# f29h85x_analog_subsys_regs register map
Vendor: Texas Instruments
Peripheral module from a debugger description file (folder HSM).
Registers are 32-bit, read-write, no defined reset value unless marked. A register's access mark holds for its fields unless they carry their own. Offsets are as the file gives them; lines under a group give offsets from that group; [hi:lo] are bit positions; {n}, {i} and the like mark numbered series; 'fields as' and 'values as' point back to an identical list; <NAME> marks a mode.

## ANALOG_SUBSYS_REGS — ANALOG SUBSYS Registers
0x44 PMMVREGTRIM — Power Management Module VREG Trim Register
  [7:0] VREGTRIM — Core VDD Voltage Regulator Trim
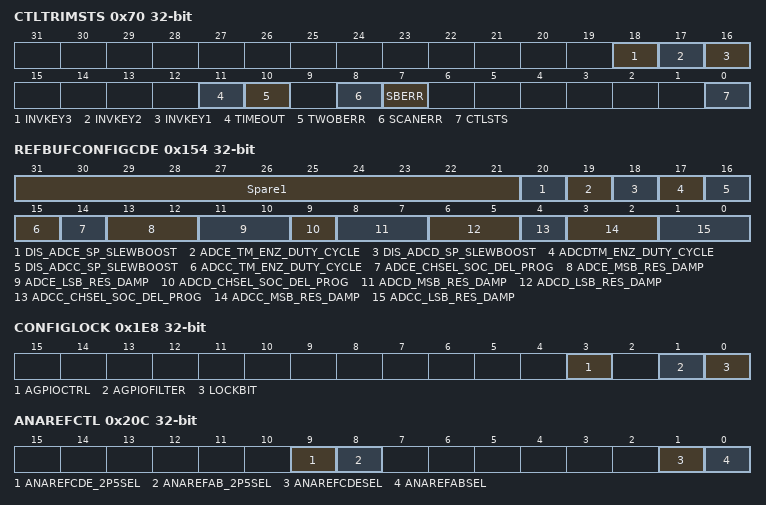
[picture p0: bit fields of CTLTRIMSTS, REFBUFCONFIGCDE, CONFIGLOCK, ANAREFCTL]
0x70 CTLTRIMSTS ro — HWCTL TRIM Error Status register
  [18] INVKEY3 — Invalid key read during TLC3
  [17] INVKEY2 — Invalid key read during TLC2
  [16] INVKEY1 — Invalid key read during TLC1
  [11] TIMEOUT — Timeout Error
  [10] TWOBERR — Two-bit error detected
  [8] SCANERR — Wrong scan chain signature
  [7] SBERR — Single-bit error detected while reading from Flash
  [0] CTLSTS — TRIM Load Complete
0x154 REFBUFCONFIGCDE — Config register for analog reference CDE
  [31:21] Spare1 — Spare1 bits
  [20] DIS_ADCE_SP_SLEWBOOST — ADC sp slew boost disbale
  [19] ADCE_TM_ENZ_DUTY_CYCLE — Disable Pulse Stretch testmode to have effect in ADC_CLK
  [18] DIS_ADCD_SP_SLEWBOOST — ADC sp slew boost disbale
  [17] ADCDTM_ENZ_DUTY_CYCLE — Disable Pulse Stretch testmode to have effect in ADC_CLK
  [16] DIS_ADCC_SP_SLEWBOOST — ADC sp slew boost disbale
  [15] ADCC_TM_ENZ_DUTY_CYCLE — Disable Pulse Stretch testmode to have effect in ADC_CLK
  [14] ADCE_CHSEL_SOC_DEL_PROG — CHSEL rise to ADCESOC rise delay program
  [13:12] ADCE_MSB_RES_DAMP — ADCE MSB damp res prog
  [11:10] ADCE_LSB_RES_DAMP — ADCE LSB damp res prog
  [9] ADCD_CHSEL_SOC_DEL_PROG — CHSEL rise to ADCDSOC rise delay program
  [8:7] ADCD_MSB_RES_DAMP — ADCD MSB damp res prog
  [6:5] ADCD_LSB_RES_DAMP — ADCD LSB damp res prog
  [4] ADCC_CHSEL_SOC_DEL_PROG — CHSEL rise to ADCCSOC rise delay program
  [3:2] ADCC_MSB_RES_DAMP — ADCC MSB damp res prog
  [1:0] ADCC_LSB_RES_DAMP — ADCC LSB damp res prog
0x1A8 INTERNALTESTCTL — INTERNALTEST Node Control Register
  [5:0] TESTSEL — Test Select
0x1E8 CONFIGLOCK — Lock Register for all the config registers.
  [3] AGPIOCTRL — Locks all AGPIOCTRL Register
  [1] AGPIOFILTER — Locks AGPIOFILTER Register
  [0] LOCKBIT — Locks analog subsystem config
0x1EC TSNSCTL — Temperature Sensor Control Register
  [0] ENABLE — Temperature Sensor Enable
0x20C ANAREFCTL — Analog Reference Control Register.
  [9] ANAREFCDE_2P5SEL — Analog Reference B Select
  [8] ANAREFAB_2P5SEL — Analog Reference Select
  [1] ANAREFCDESEL — Analog Reference ADC-C/D/E Select
  [0] ANAREFABSEL — Analog Reference ADC-A/B Select
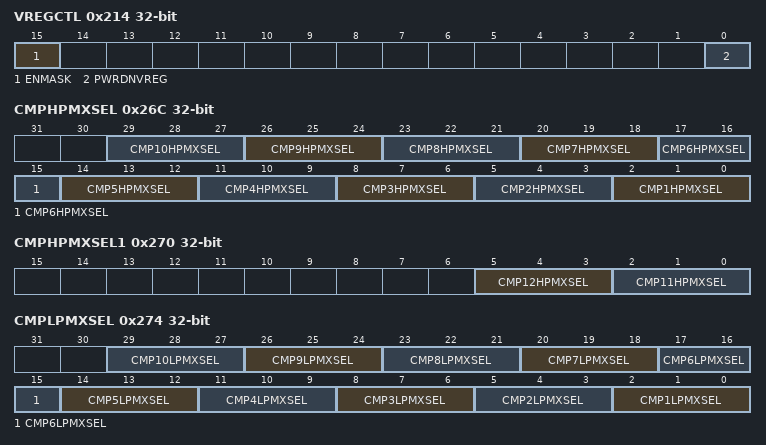
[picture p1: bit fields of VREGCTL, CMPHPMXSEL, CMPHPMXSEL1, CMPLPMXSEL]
0x214 VREGCTL — Voltage Regulator Control Register
  [15] ENMASK — Enable VMON function mask on a TRIM load
  [0] PWRDNVREG — Power down internal voltage regulator
0x22C VMONCTL — Voltage Monitor Control Register
  [8] BORLVMONDIS — Disable BORL(ow) feature on VDDIO
0x26C CMPHPMXSEL — Bits to select one of the many sources on CopmHP inputs. Refer to Pimux diagram for details.
  [3n-1:3n-3] CMP{n}HPMXSEL (n=1..10) — CMP{n}HPMXSEL bits
0x270 CMPHPMXSEL1 — Bits to select one of the many sources on CopmHP inputs. Refer to Pimux diagram for details.
  [5:3] CMP12HPMXSEL — CMP12HPMXSEL bits
  [2:0] CMP11HPMXSEL — CMP11HPMXSEL bits
0x274 CMPLPMXSEL — Bits to select one of the many sources on CopmLP inputs. Refer to Pimux diagram for details.
  [3n-1:3n-3] CMP{n}LPMXSEL (n=1..10) — CMP{n}LPMXSEL bits
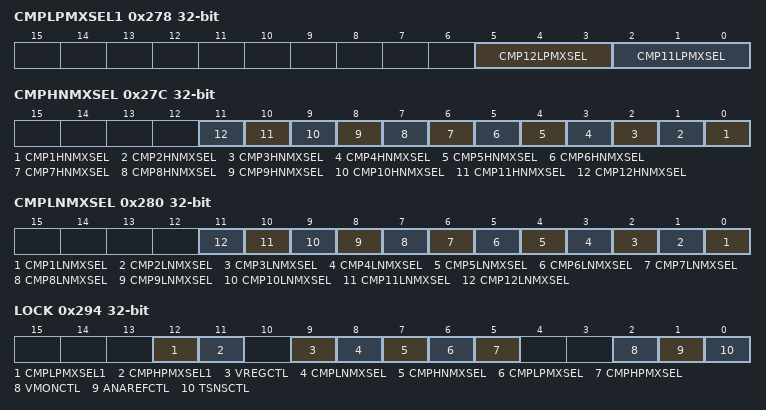
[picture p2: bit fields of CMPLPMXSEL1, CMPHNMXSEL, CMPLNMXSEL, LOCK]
0x278 CMPLPMXSEL1 — Bits to select one of the many sources on CopmLP inputs. Refer to Pimux diagram for details.
  [5:3] CMP12LPMXSEL — CMP12LPMXSEL bits
  [2:0] CMP11LPMXSEL — CMP11LPMXSEL bits
0x27C CMPHNMXSEL — Bits to select one of the many sources on CopmHN inputs. Refer to Pimux diagram for details.
  [n-1] CMP{n}HNMXSEL (n=1..12) — CMP{n}HNMXSEL bits
0x280 CMPLNMXSEL — Bits to select one of the many sources on CopmLN inputs. Refer to Pimux diagram for details.
  [n-1] CMP{n}LNMXSEL (n=1..12) — CMP{n}LNMXSEL bits
0x294 LOCK
  [12] CMPLPMXSEL1 — CMPLPMXSEL1 Register lock bit
  [11] CMPHPMXSEL1 — CMPHPMXSEL1 Register lock bit
  [9] VREGCTL — VREGCTL Register lock bit
  [8] CMPLNMXSEL — CMPLNMXSEL Register lock bit
  [7] CMPHNMXSEL — CMPHNMXSEL Register lock bit
  [6] CMPLPMXSEL — CMPLPMXSEL Register lock bit
  [5] CMPHPMXSEL — CMPHPMXSEL Register lock bit
  [2] VMONCTL — VMONCTL Register lock bit
  [1] ANAREFCTL — ANAREFCTL Register lock bit
  [0] TSNSCTL — TSNSCTL Register lock bit
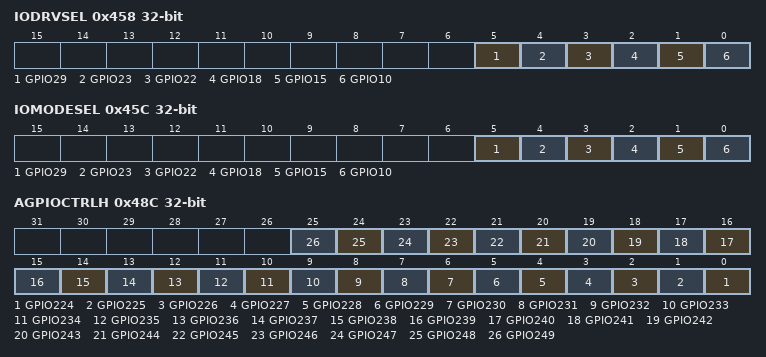
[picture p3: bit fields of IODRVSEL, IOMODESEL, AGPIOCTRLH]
0x458 IODRVSEL — 5V FS IO Drive strength select register
  [5] GPIO29 — Drive select for GPIO29
  [4] GPIO23 — Drive select for GPIO23
  [3] GPIO22 — Drive select for GPIO22
  [2] GPIO18 — Drive select for GPIO18
  [1] GPIO15 — Drive select for GPIO15
  [0] GPIO10 — Drive select for GPIO10
0x45C IOMODESEL — PMBUS IO Mode select register
  [5] GPIO29 — Mode select for GPIO29
  [4] GPIO23 — Mode select for GPIO23
  [3] GPIO22 — Mode select for GPIO22
  [2] GPIO18 — Mode select for GPIO18
  [1] GPIO15 — Mode select for GPIO15
  [0] GPIO10 — Mode select for GPIO10
0x464 AGPIOFILTER — AGPIO Filter Control Register
  [1:0] FILTER — AGPIOFILTER Control for filter ALL AGPIO pins
0x48C AGPIOCTRLH — AGPIO Control Register
  [n-224] GPIO{n} (n=224..249) — AGPIOCTRL for GPIO{n}
0x4B4 PARITY_TEST — Enables parity test
  [3:0] TESTEN — Parity test enable configuration
